# nrf9230_enga_secure register map
Vendor: Nordic Semiconductor; Series: nRF92; File version: 1
CPU: CM33 r0p4, little endian, MPU, no FPU, 3 interrupt priority bits, 480 interrupts, 4 SAU regions
Registers are 32-bit, read-write, reset 0x0 unless marked. A register's access mark holds for its fields unless they carry their own. Offsets are from the block's base; [hi:lo] are bit positions; lines under a group give offsets from that group; {n}, {i} and the like mark numbered series; 'fields as' and 'values as' point back to an identical list.

## PCGCS000_S — PCGCSlave 0
Base 0x5100A000
Same registers: PCGCS010_S 0x5101A000
{0xC00+4i} PENALTY[{i}] (i=0..1) reset 0xFFFFFFFC — Description collection: Penalty level for power/clock pair n. When FULL_PCP_ZERO feature is not supported, PENALTY[0] address overlaps the PENALTY0 address and register description for PENALTY[0] is not valid.
  [1:0] PENALTY — Penalty level
0xC00 PENALTY0 (alternate view of PENALTY[*]) — Penalty level for power/clock pair 0. The register description is valid only when FULL_PCP_ZERO feature is not supported
  [1:0] PENALTY ro — Penalty level
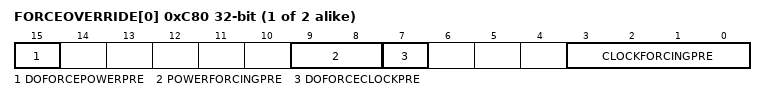
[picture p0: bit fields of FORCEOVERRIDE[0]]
{0xC80+4i} FORCEOVERRIDE[{i}] (i=0..1) — Description collection: Force override of power/clock pair n.
  [15] DOFORCEPOWERPRE, [9:8] POWERFORCINGPRE, [7] DOFORCECLOCKPRE, [3:0] CLOCKFORCINGPRE

## PCGCM000_S — PCGC Master 0
Base 0x5100B000
Same registers: PCGCM001_S 0x5100F000, PCGCM010_S 0x5101B000, PCGCM011_S 0x5101F000
{0xE0+4i} SETPWRCONTHRESHOLDBASE[{i}] (i=0..2) — Description collection: Set power consumption threshold base for power source / regulator n
  [3:0] SETPWRCONTHRESHOLDBASE
0xC00 UNLOCKBACKDOORS
  [15:0] UNLOCKBACKDOORS — Write: 0x00009375 to lock/unlock backdoors Read: 0x00000001 if backdoors is enabled Read: 0x00000000 if backdoors is disabled
0xC04 ENABLEPOWERREGFORCE
  [2:0] ENABLEPOWERREGFORCE
0xC08 POWERREGFORCE — Force reg
  [2:0] POWERREGFORCEREG
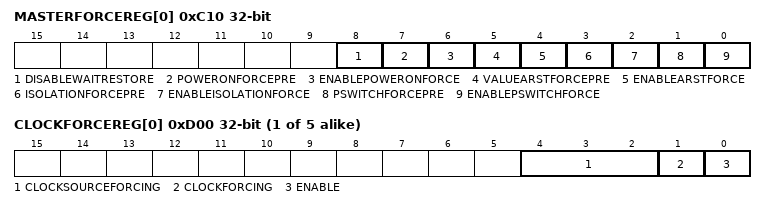
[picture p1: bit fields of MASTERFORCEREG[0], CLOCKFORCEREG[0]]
{0xC10+4i} MASTERFORCEREG[{i}] (i=0..0) — Description collection: Force reg
  [8] DISABLEWAITRESTORE — Turn off waiting for arst deactivation before retention restore
    1=Disable (Turn off waiting for arst deactivation before retention restore); 0=Enable (Wait for arst deactivation before retention restore)
  [7] POWERONFORCEPRE
  [6] ENABLEPOWERONFORCE
  [5] VALUEARSTFORCEPRE
  [4] ENABLEARSTFORCE
  [3] ISOLATIONFORCEPRE
  [2] ENABLEISOLATIONFORCE
  [1] PSWITCHFORCEPRE
  [0] ENABLEPSWITCHFORCE
{0xD00+4i} CLOCKFORCEREG[{i}] (i=0..4) — Description collection: Force clock n
  [4:2] CLOCKSOURCEFORCING
  [1] CLOCKFORCING
  [0] ENABLE — Enable clock forcing

## CPUCONF_NS — CPU Configuration 0
Base 0x41011000
Same registers: CPUCONF_S 0x51011000
0x00 TASKS_ERASECACHE wo — Erase the caches used by the CPU.
  [0] TASKS_ERASECACHE
    1=Trigger task
0x500 INITSVTOR reset 0x1000000 — Initial value of the secure VTOR (Vector Table Offset Register) after CPU reset.
  [31:0] INITSVTOR — Initial value of the VTOR.
0x504 INITNSVTOR reset 0x1000000 — Initial value of the non-secure VTOR (Vector Table Offset Register).
  [31:0] INITNSVTOR — Initial value of the VTOR.
0x508 CPUSTART reset 0x1 — Enable for starting the CPU
  [0] EN — Enable to start the CPU.
    0=Stopped (CPU stopped.); 1=Started (CPU started.)
0x50C CPUWAIT — Enable for the CPU wait.
  [0] EN — Enable to the CPU wait.
    0=Disabled (CPU is not waiting.); 1=Enabled (CPU is waiting.)

## MUTEX_NS — MUTEX 0
Base 0x41017000
Same registers: MUTEX_S 0x51017000
{0x400+4i} MUTEX[{i}] (i=0..7) — Description collection: Mutex register
  [0] MUTEX — Mutex register n
    0=Unlocked (Mutex n is in unlocked state); 1=Locked (Mutex n is in locked state)

## BILS_S — The Built-in Leakage Sensor (BILS) module.
Base 0x51019000
0x400 CONFIG group — Unspecified
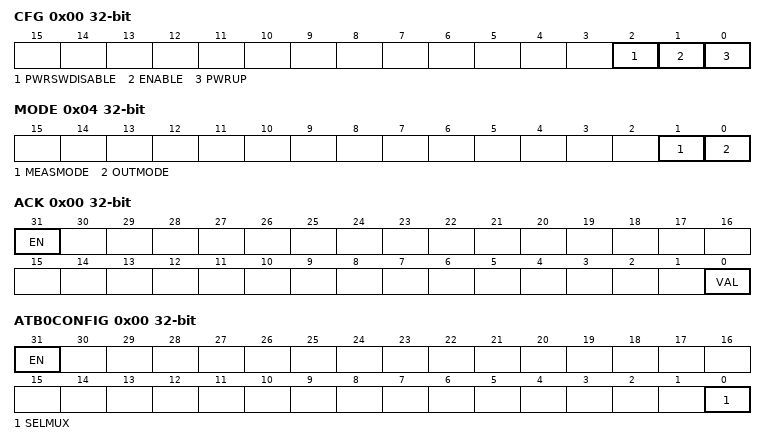
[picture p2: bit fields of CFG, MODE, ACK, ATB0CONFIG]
  0x00 CFG — BILS configuration
    [2] PWRSWDISABLE — Disable power switch.
      0=PwrSwNormalMode (Normal control of the power switch.); 1=PwrSwDisabledMode (Power switch is turned off.)
    [1] ENABLE — BILS enable
      0=BilsDisable (Disable BILS, REQ_SWOFF_AO_0V8 = 0); 1=BilsEnable (Enable BILS, REQ_SWOFF_AO_0V8 is controlled by BILS)
    [0] PWRUP — Power up BILS
      0=PwrOff (BILS is powered down and REQ_SWOFF_AO_0V8=0); 1=PwrOn (BILS is powered up)
  0x04 MODE — Mode selection
    [1] MEASMODE — Measurement mode selection
      0=MeasDisMode (Measure discharge rate); 1=MeasPwMode (Measure power switch chain propagation delay)
    [0] OUTMODE — Output mode selection
      0=Duty50Mode (50:50 duty cycle output selected to FOUT_AO_0V8 pin); 1=CompMode (Comparator output selected to FOUT_AO_0V8 pin)
0x500 OVERRIDE group — Unspecified
  0x00 ACK — Override the ACL_SWOFF_0V8 signal
    [31] EN — Override enable
      0=Disabled (Override disabled); 1=Enabled (Override is enabled)
    [0] VAL — Override value
0x600 DFT group — Unspecified
  0x00 ATB0CONFIG — Analog Test Bus 0 (ATB0) configuration
    [31] EN — Enable the analog test bus
      0=Disabled (Analog test bus is disabled); 1=Enabled (Analog test bus is enabled)
    [0] SELMUX — Select multiplexer for ATB0
      0=None selected; 1=Connect (Voltage on ATB0 used as threshold voltage)
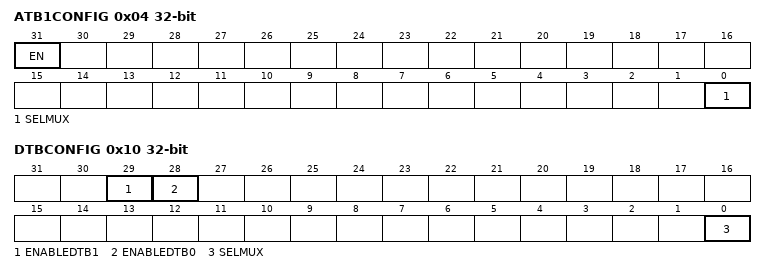
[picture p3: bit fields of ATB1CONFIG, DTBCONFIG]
  0x04 ATB1CONFIG — Analog Test Bus 1 (ATB1) configuration
    [31] EN — Enable the analog test bus
      values as DFT.ATB0CONFIG.EN
    [0] SELMUX — Select multiplexer for ATB1
      0=None selected; 1=ConnectDVDD (ATB1 connected to DVDD_0V8_SW)
  0x10 DTBCONFIG — Digital Test Bus configuration
    [29] ENABLEDTB1 — Enable the digital test bus
      0=Disabled (Digital test bus is disabled); 1=Enabled (Digital test bus is enabled)
    [28] ENABLEDTB0 — Enable the digital test bus
      values as ENABLEDTB1
    [0] SELMUX — Select multiplexer for DTB0
      0=None selected; 1=Connect (FOUT_AO_0V8 is connected to DTB0, REQ_SWOFF_AO_0V8 is connected to DTB1)
